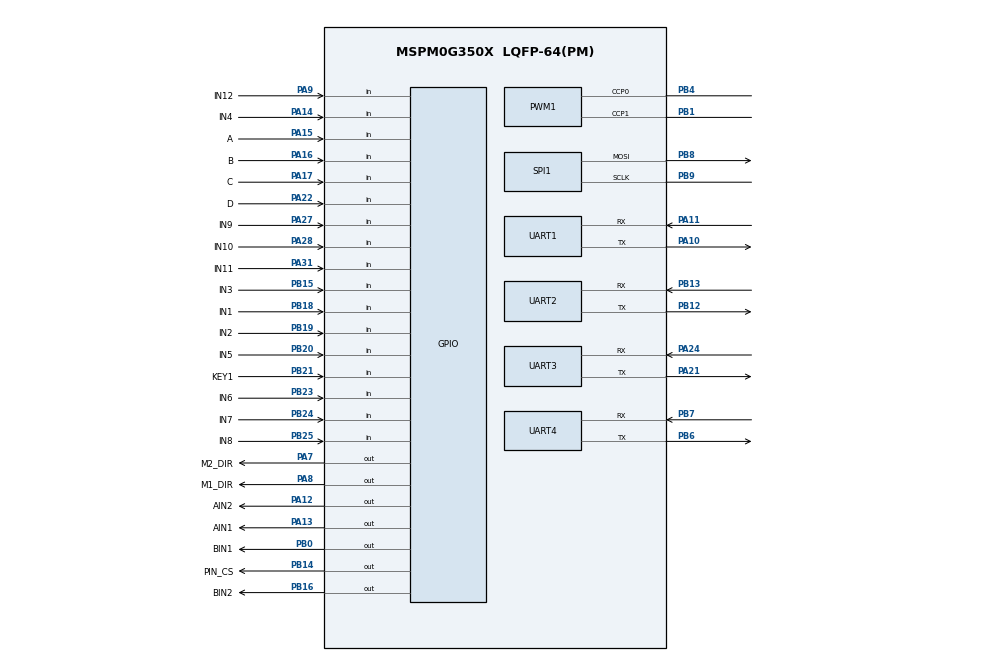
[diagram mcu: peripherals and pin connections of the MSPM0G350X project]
/**
 * @cliArgs --device "MSPM0G350X" --part "Default" --package "LQFP-64(PM)" --product "mspm0_sdk@2.05.01.01"
 * @versions {"tool":"1.24.0+4150"}
 */

/**
 * Import the modules used in this configuration.
 */
const GPIO   = scripting.addModule("/ti/driverlib/GPIO", {}, false);
const GPIO1  = GPIO.addInstance();
const GPIO2  = GPIO.addInstance();
const GPIO4  = GPIO.addInstance();
const GPIO5  = GPIO.addInstance();
const GPIO6  = GPIO.addInstance();
const GPIO7  = GPIO.addInstance();
const GPIO8  = GPIO.addInstance();
const GPIO9  = GPIO.addInstance();
const PWM    = scripting.addModule("/ti/driverlib/PWM", {}, false);
const PWM1   = PWM.addInstance();
const SPI    = scripting.addModule("/ti/driverlib/SPI", {}, false);
const SPI1   = SPI.addInstance();
const SYSCTL = scripting.addModule("/ti/driverlib/SYSCTL");
const TIMER  = scripting.addModule("/ti/driverlib/TIMER", {}, false);
const TIMER1 = TIMER.addInstance();
const TIMER2 = TIMER.addInstance();
const TIMER3 = TIMER.addInstance();
const TIMER4 = TIMER.addInstance();
const UART   = scripting.addModule("/ti/driverlib/UART", {}, false);
const UART1  = UART.addInstance();
const UART2  = UART.addInstance();
const UART3  = UART.addInstance();
const UART4  = UART.addInstance();

/**
 * Write custom configuration values to the imported modules.
 */
const divider9       = system.clockTree["UDIV"];
divider9.divideValue = 2;

const multiplier2         = system.clockTree["PLL_QDIV"];
multiplier2.multiplyValue = 4;

const mux4       = system.clockTree["EXHFMUX"];
mux4.inputSelect = "EXHFMUX_XTAL";

const mux8       = system.clockTree["HSCLKMUX"];
mux8.inputSelect = "HSCLKMUX_SYSPLL0";

const mux12       = system.clockTree["SYSPLLMUX"];
mux12.inputSelect = "zSYSPLLMUX_HFCLK";

const pinFunction4       = system.clockTree["HFXT"];
pinFunction4.inputFreq   = 40;
pinFunction4.enable      = true;
pinFunction4.HFXTStartup = 10;

GPIO1.$name                              = "LED";
GPIO1.associatedPins.create(2);
GPIO1.associatedPins[0].$name            = "LED3";
GPIO1.associatedPins[0].internalResistor = "PULL_DOWN";
GPIO1.associatedPins[0].assignedPort     = "PORTB";
GPIO1.associatedPins[0].assignedPin      = "22";
GPIO1.associatedPins[1].$name            = "LED1";
GPIO1.associatedPins[1].internalResistor = "PULL_DOWN";
GPIO1.associatedPins[1].assignedPort     = "PORTB";
GPIO1.associatedPins[1].assignedPin      = "27";
GPIO1.associatedPins[1].initialValue     = "SET";

const Board = scripting.addModule("/ti/driverlib/Board", {}, false);

GPIO2.$name                              = "KEY";
GPIO2.associatedPins.create(3);
GPIO2.associatedPins[0].$name            = "KEY1";
GPIO2.associatedPins[0].direction        = "INPUT";
GPIO2.associatedPins[0].assignedPort     = "PORTB";
GPIO2.associatedPins[0].assignedPin      = "21";
GPIO2.associatedPins[0].internalResistor = "PULL_UP";
GPIO2.associatedPins[0].pin.$assign      = "PB21";
GPIO2.associatedPins[1].$name            = "KEY2";
GPIO2.associatedPins[1].direction        = "INPUT";
GPIO2.associatedPins[1].assignedPort     = "PORTA";
GPIO2.associatedPins[1].assignedPin      = "26";
GPIO2.associatedPins[1].internalResistor = "PULL_UP";
GPIO2.associatedPins[2].$name            = "KEY3";
GPIO2.associatedPins[2].direction        = "INPUT";
GPIO2.associatedPins[2].assignedPort     = "PORTA";
GPIO2.associatedPins[2].assignedPin      = "25";
GPIO2.associatedPins[2].internalResistor = "PULL_UP";

GPIO4.$name                              = "Encoder";
GPIO4.port                               = "PORTA";
GPIO4.associatedPins.create(4);
GPIO4.associatedPins[0].$name            = "A";
GPIO4.associatedPins[0].direction        = "INPUT";
GPIO4.associatedPins[0].internalResistor = "PULL_UP";
GPIO4.associatedPins[0].interruptEn      = true;
GPIO4.associatedPins[0].polarity         = "RISE_FALL";
GPIO4.associatedPins[0].assignedPin      = "15";
GPIO4.associatedPins[0].pin.$assign      = "PA15";
GPIO4.associatedPins[1].$name            = "B";
GPIO4.associatedPins[1].direction        = "INPUT";
GPIO4.associatedPins[1].internalResistor = "PULL_UP";
GPIO4.associatedPins[1].interruptEn      = true;
GPIO4.associatedPins[1].polarity         = "RISE_FALL";
GPIO4.associatedPins[1].assignedPin      = "16";
GPIO4.associatedPins[1].pin.$assign      = "PA16";
GPIO4.associatedPins[2].$name            = "C";
GPIO4.associatedPins[2].direction        = "INPUT";
GPIO4.associatedPins[2].internalResistor = "PULL_UP";
GPIO4.associatedPins[2].interruptEn      = true;
GPIO4.associatedPins[2].polarity         = "RISE_FALL";
GPIO4.associatedPins[2].assignedPin      = "17";
GPIO4.associatedPins[2].pin.$assign      = "PA17";
GPIO4.associatedPins[3].$name            = "D";
GPIO4.associatedPins[3].direction        = "INPUT";
GPIO4.associatedPins[3].internalResistor = "PULL_UP";
GPIO4.associatedPins[3].interruptEn      = true;
GPIO4.associatedPins[3].polarity         = "RISE_FALL";
GPIO4.associatedPins[3].assignedPin      = "22";
GPIO4.associatedPins[3].pin.$assign      = "PA22";

GPIO5.$name                          = "Motor_Ctrl";
GPIO5.associatedPins.create(4);
GPIO5.associatedPins[0].$name        = "AIN1";
GPIO5.associatedPins[0].assignedPort = "PORTA";
GPIO5.associatedPins[0].assignedPin  = "13";
GPIO5.associatedPins[0].pin.$assign  = "PA13";
GPIO5.associatedPins[1].$name        = "AIN2";
GPIO5.associatedPins[1].assignedPort = "PORTA";
GPIO5.associatedPins[1].assignedPin  = "12";
GPIO5.associatedPins[1].pin.$assign  = "PA12";
GPIO5.associatedPins[2].$name        = "BIN1";
GPIO5.associatedPins[2].assignedPort = "PORTB";
GPIO5.associatedPins[2].assignedPin  = "0";
GPIO5.associatedPins[2].pin.$assign  = "PB0";
GPIO5.associatedPins[3].$name        = "BIN2";
GPIO5.associatedPins[3].assignedPort = "PORTB";
GPIO5.associatedPins[3].assignedPin  = "16";
GPIO5.associatedPins[3].pin.$assign  = "PB16";

GPIO6.$name                          = "Huidu";
GPIO6.associatedPins.create(12);
GPIO6.associatedPins[0].$name        = "IN1";
GPIO6.associatedPins[0].direction    = "INPUT";
GPIO6.associatedPins[0].pin.$assign  = "PB18";
GPIO6.associatedPins[1].$name        = "IN2";
GPIO6.associatedPins[1].direction    = "INPUT";
GPIO6.associatedPins[1].pin.$assign  = "PB19";
GPIO6.associatedPins[2].$name        = "IN3";
GPIO6.associatedPins[2].direction    = "INPUT";
GPIO6.associatedPins[2].pin.$assign  = "PB15";
GPIO6.associatedPins[3].$name        = "IN4";
GPIO6.associatedPins[3].direction    = "INPUT";
GPIO6.associatedPins[3].pin.$assign  = "PA14";
GPIO6.associatedPins[4].$name        = "IN5";
GPIO6.associatedPins[4].direction    = "INPUT";
GPIO6.associatedPins[4].pin.$assign  = "PB20";
GPIO6.associatedPins[5].$name        = "IN6";
GPIO6.associatedPins[5].direction    = "INPUT";
GPIO6.associatedPins[5].pin.$assign  = "PB23";
GPIO6.associatedPins[6].$name        = "IN7";
GPIO6.associatedPins[6].direction    = "INPUT";
GPIO6.associatedPins[6].pin.$assign  = "PB24";
GPIO6.associatedPins[7].$name        = "IN8";
GPIO6.associatedPins[7].direction    = "INPUT";
GPIO6.associatedPins[7].pin.$assign  = "PB25";
GPIO6.associatedPins[8].$name        = "IN9";
GPIO6.associatedPins[8].direction    = "INPUT";
GPIO6.associatedPins[8].pin.$assign  = "PA27";
GPIO6.associatedPins[9].$name        = "IN10";
GPIO6.associatedPins[9].direction    = "INPUT";
GPIO6.associatedPins[9].pin.$assign  = "PA28";
GPIO6.associatedPins[10].$name       = "IN11";
GPIO6.associatedPins[10].direction   = "INPUT";
GPIO6.associatedPins[10].pin.$assign = "PA31";
GPIO6.associatedPins[11].$name       = "IN12";
GPIO6.associatedPins[11].direction   = "INPUT";
GPIO6.associatedPins[11].pin.$assign = "PA9";

GPIO7.$name                          = "GPIO_LCD";
GPIO7.associatedPins.create(4);
GPIO7.associatedPins[0].$name        = "PIN_RES";
GPIO7.associatedPins[0].assignedPort = "PORTB";
GPIO7.associatedPins[0].assignedPin  = "10";
GPIO7.associatedPins[1].$name        = "PIN_DC";
GPIO7.associatedPins[1].assignedPort = "PORTB";
GPIO7.associatedPins[1].assignedPin  = "11";
GPIO7.associatedPins[2].$name        = "PIN_CS";
GPIO7.associatedPins[2].initialValue = "SET";
GPIO7.associatedPins[2].assignedPort = "PORTB";
GPIO7.associatedPins[2].assignedPin  = "14";
GPIO7.associatedPins[2].pin.$assign  = "PB14";
GPIO7.associatedPins[3].$name        = "PIN_BLK";
GPIO7.associatedPins[3].assignedPort = "PORTB";
GPIO7.associatedPins[3].assignedPin  = "26";

GPIO8.$name                              = "IIC_Software";
GPIO8.port                               = "PORTA";
GPIO8.associatedPins.create(2);
GPIO8.associatedPins[0].$name            = "JYSCL";
GPIO8.associatedPins[0].initialValue     = "SET";
GPIO8.associatedPins[0].internalResistor = "PULL_UP";
GPIO8.associatedPins[0].assignedPin      = "1";
GPIO8.associatedPins[1].$name            = "JYSDA";
GPIO8.associatedPins[1].initialValue     = "SET";
GPIO8.associatedPins[1].internalResistor = "PULL_UP";
GPIO8.associatedPins[1].assignedPin      = "0";

GPIO9.$name                         = "STEP_MOTOR";
GPIO9.associatedPins.create(2);
GPIO9.associatedPins[0].$name       = "M1_DIR";
GPIO9.associatedPins[0].pin.$assign = "PA8";
GPIO9.associatedPins[1].$name       = "M2_DIR";
GPIO9.associatedPins[1].pin.$assign = "PA7";

PWM1.$name                      = "PWM_0";
PWM1.timerCount                 = 10000;
PWM1.timerStartTimer            = true;
PWM1.pwmMode                    = "EDGE_ALIGN_UP";
PWM1.clockDivider               = 5;
PWM1.clockPrescale              = 4;
PWM1.peripheral.$assign         = "TIMA1";
PWM1.peripheral.ccp0Pin.$assign = "PB4";
PWM1.peripheral.ccp1Pin.$assign = "PB1";
PWM1.PWM_CHANNEL_0.$name        = "ti_driverlib_pwm_PWMTimerCC0";
PWM1.PWM_CHANNEL_1.$name        = "ti_driverlib_pwm_PWMTimerCC1";
PWM1.ccp0PinConfig.$name        = "ti_driverlib_gpio_GPIOPinGeneric4";
PWM1.ccp1PinConfig.$name        = "ti_driverlib_gpio_GPIOPinGeneric5";

SPI1.$name                              = "SPI_LCD";
SPI1.targetBitRate                      = 32000000;
SPI1.frameFormat                        = "MOTO3";
SPI1.direction                          = "PICO";
SPI1.sclkPinConfig.direction            = scripting.forceWrite("OUTPUT");
SPI1.sclkPinConfig.onlyInternalResistor = scripting.forceWrite(false);
SPI1.sclkPinConfig.passedPeripheralType = scripting.forceWrite("Digital");
SPI1.sclkPinConfig.$name                = "ti_driverlib_gpio_GPIOPinGeneric10";
SPI1.mosiPinConfig.direction            = scripting.forceWrite("OUTPUT");
SPI1.mosiPinConfig.hideOutputInversion  = scripting.forceWrite(false);
SPI1.mosiPinConfig.onlyInternalResistor = scripting.forceWrite(false);
SPI1.mosiPinConfig.passedPeripheralType = scripting.forceWrite("Digital");
SPI1.mosiPinConfig.$name                = "ti_driverlib_gpio_GPIOPinGeneric11";
SPI1.peripheral.sclkPin.$assign         = "PB9";
SPI1.peripheral.mosiPin.$assign         = "PB8";

SYSCTL.clockTreeEn           = true;
SYSCTL.forceDefaultClkConfig = true;
SYSCTL.validateClkStatus     = true;

TIMER1.$name              = "TIMER_0";
TIMER1.timerClkDiv        = 8;
TIMER1.timerClkPrescale   = 8;
TIMER1.timerStartTimer    = true;
TIMER1.timerMode          = "PERIODIC_UP";
TIMER1.timerPeriod        = "1 ms";
TIMER1.interrupts         = ["ZERO"];
TIMER1.peripheral.$assign = "TIMG8";

TIMER2.$name              = "TIMER_1";
TIMER2.timerClkDiv        = 8;
TIMER2.timerClkPrescale   = 100;
TIMER2.timerMode          = "PERIODIC";
TIMER2.timerStartTimer    = true;
TIMER2.interrupts         = ["ZERO"];
TIMER2.timerPeriod        = "3 ms";
TIMER2.peripheral.$assign = "TIMG0";

TIMER3.$name              = "TIMER_2";
TIMER3.timerClkDiv        = 8;
TIMER3.timerClkPrescale   = 8;
TIMER3.timerMode          = "PERIODIC_UP";
TIMER3.timerPeriod        = "0.01 ms";
TIMER3.timerStartTimer    = true;
TIMER3.interrupts         = ["LOAD"];
TIMER3.peripheral.$assign = "TIMG7";

TIMER4.$name            = "TIMER_MOTOR";
TIMER4.timerPeriod      = "5 ms";
TIMER4.timerClkDiv      = 8;
TIMER4.timerClkPrescale = 8;
TIMER4.interrupts       = ["ZERO"];

UART1.$name                    = "UART_0";
UART1.enabledInterrupts        = ["RX"];
UART1.interruptPriority        = "0";
UART1.targetBaudRate           = 115200;
UART1.peripheral.$assign       = "UART0";
UART1.peripheral.rxPin.$assign = "PA11";
UART1.peripheral.txPin.$assign = "PA10";
UART1.txPinConfig.$name        = "ti_driverlib_gpio_GPIOPinGeneric2";
UART1.rxPinConfig.$name        = "ti_driverlib_gpio_GPIOPinGeneric3";

UART2.targetBaudRate                   = 115200;
UART2.$name                            = "UART_MOTOR";
UART2.enableFIFO                       = true;
UART2.rxFifoThreshold                  = "DL_UART_RX_FIFO_LEVEL_ONE_ENTRY";
UART2.enableDMARX                      = false;
UART2.enableDMATX                      = false;
UART2.enabledInterrupts                = ["RX"];
UART2.peripheral.$assign               = "UART3";
UART2.peripheral.rxPin.$assign         = "PB13";
UART2.peripheral.txPin.$assign         = "PB12";
UART2.txPinConfig.direction            = scripting.forceWrite("OUTPUT");
UART2.txPinConfig.hideOutputInversion  = scripting.forceWrite(false);
UART2.txPinConfig.onlyInternalResistor = scripting.forceWrite(false);
UART2.txPinConfig.passedPeripheralType = scripting.forceWrite("Digital");
UART2.txPinConfig.$name                = "ti_driverlib_gpio_GPIOPinGeneric6";
UART2.rxPinConfig.hideOutputInversion  = scripting.forceWrite(false);
UART2.rxPinConfig.onlyInternalResistor = scripting.forceWrite(false);
UART2.rxPinConfig.passedPeripheralType = scripting.forceWrite("Digital");
UART2.rxPinConfig.$name                = "ti_driverlib_gpio_GPIOPinGeneric7";

UART3.$name                            = "UART_MOTOR_2";
UART3.targetBaudRate                   = 115200;
UART3.enableFIFO                       = true;
UART3.rxFifoThreshold                  = "DL_UART_RX_FIFO_LEVEL_ONE_ENTRY";
UART3.enabledInterrupts                = ["RX"];
UART3.peripheral.$assign               = "UART2";
UART3.peripheral.rxPin.$assign         = "PA24";
UART3.peripheral.txPin.$assign         = "PA21";
UART3.txPinConfig.direction            = scripting.forceWrite("OUTPUT");
UART3.txPinConfig.hideOutputInversion  = scripting.forceWrite(false);
UART3.txPinConfig.onlyInternalResistor = scripting.forceWrite(false);
UART3.txPinConfig.passedPeripheralType = scripting.forceWrite("Digital");
UART3.txPinConfig.$name                = "ti_driverlib_gpio_GPIOPinGeneric0";
UART3.rxPinConfig.hideOutputInversion  = scripting.forceWrite(false);
UART3.rxPinConfig.onlyInternalResistor = scripting.forceWrite(false);
UART3.rxPinConfig.passedPeripheralType = scripting.forceWrite("Digital");
UART3.rxPinConfig.$name                = "ti_driverlib_gpio_GPIOPinGeneric1";

UART4.enableFIFO                       = true;
UART4.rxFifoThreshold                  = "DL_UART_RX_FIFO_LEVEL_ONE_ENTRY";
UART4.enabledInterrupts                = ["RX"];
UART4.$name                            = "UART_1";
UART4.targetBaudRate                   = 115200;
UART4.peripheral.$assign               = "UART1";
UART4.peripheral.rxPin.$assign         = "PB7";
UART4.peripheral.txPin.$assign         = "PB6";
UART4.txPinConfig.direction            = scripting.forceWrite("OUTPUT");
UART4.txPinConfig.hideOutputInversion  = scripting.forceWrite(false);
UART4.txPinConfig.onlyInternalResistor = scripting.forceWrite(false);
UART4.txPinConfig.passedPeripheralType = scripting.forceWrite("Digital");
UART4.txPinConfig.$name                = "ti_driverlib_gpio_GPIOPinGeneric8";
UART4.rxPinConfig.hideOutputInversion  = scripting.forceWrite(false);
UART4.rxPinConfig.onlyInternalResistor = scripting.forceWrite(false);
UART4.rxPinConfig.passedPeripheralType = scripting.forceWrite("Digital");
UART4.rxPinConfig.$name                = "ti_driverlib_gpio_GPIOPinGeneric9";

/**
 * Pinmux solution for unlocked pins/peripherals. This ensures that minor changes to the automatic solver in a future
 * version of the tool will not impact the pinmux you originally saw.  These lines can be completely deleted in order to
 * re-solve from scratch.
 */
pinFunction4.peripheral.$suggestSolution           = "SYSCTL";
pinFunction4.peripheral.hfxInPin.$suggestSolution  = "PA5";
pinFunction4.peripheral.hfxOutPin.$suggestSolution = "PA6";
GPIO1.associatedPins[0].pin.$suggestSolution       = "PB22";
GPIO1.associatedPins[1].pin.$suggestSolution       = "PB27";
Board.peripheral.$suggestSolution                  = "DEBUGSS";
Board.peripheral.swclkPin.$suggestSolution         = "PA20";
Board.peripheral.swdioPin.$suggestSolution         = "PA19";
GPIO2.associatedPins[1].pin.$suggestSolution       = "PA26";
GPIO2.associatedPins[2].pin.$suggestSolution       = "PA25";
GPIO7.associatedPins[0].pin.$suggestSolution       = "PB10";
GPIO7.associatedPins[1].pin.$suggestSolution       = "PB11";
GPIO7.associatedPins[3].pin.$suggestSolution       = "PB26";
GPIO8.associatedPins[0].pin.$suggestSolution       = "PA1";
GPIO8.associatedPins[1].pin.$suggestSolution       = "PA0";
SPI1.peripheral.$suggestSolution                   = "SPI1";
TIMER4.peripheral.$suggestSolution                 = "TIMA0";
